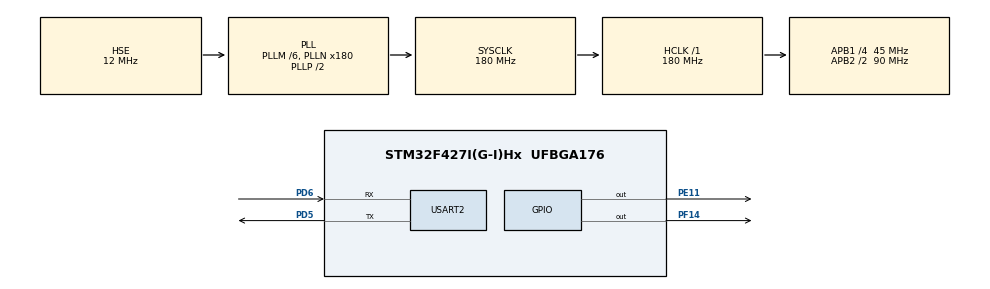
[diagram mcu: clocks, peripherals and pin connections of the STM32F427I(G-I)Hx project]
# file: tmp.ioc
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Dma.Request0=USART2_TX
Dma.USART2_TX.0.Direction=DMA_MEMORY_TO_PERIPH
Dma.USART2_TX.0.FIFOMode=DMA_FIFOMODE_DISABLE
Dma.USART2_TX.0.Instance=DMA1_Stream6
Dma.USART2_TX.0.MemDataAlignment=DMA_MDATAALIGN_BYTE
Dma.USART2_TX.0.MemInc=DMA_MINC_ENABLE
Dma.USART2_TX.0.Mode=DMA_NORMAL
Dma.USART2_TX.0.PeriphDataAlignment=DMA_PDATAALIGN_BYTE
Dma.USART2_TX.0.PeriphInc=DMA_PINC_DISABLE
Dma.USART2_TX.0.Priority=DMA_PRIORITY_LOW
Mcu.Family=STM32F4
Mcu.Name=STM32F427I(G-I)Hx
Mcu.Package=UFBGA176
NVIC.DMA1_Stream6_IRQn=true\:0\:0\:false\:false\:true\:false
NVIC.PriorityGroup=NVIC_PRIORITYGROUP_4
NVIC.RCC_IRQn=true\:0\:0\:false\:false\:true\:true
NVIC.USART2_IRQn=true\:0\:0\:false\:false\:true\:true
PD5.Mode=Asynchronous
PD5.Signal=USART2_TX
PD6.Mode=Asynchronous
PD6.Signal=USART2_RX
PE11.PinState=GPIO_PIN_SET
PE11.Signal=GPIO_Output
PF14.PinState=GPIO_PIN_SET
PF14.Signal=GPIO_Output
PH0/OSC_IN.Mode=HSE-External-Oscillator
PH0/OSC_IN.Signal=RCC_OSC_IN
PH1/OSC_OUT.Mode=HSE-External-Oscillator
PH1/OSC_OUT.Signal=RCC_OSC_OUT
ProjectManager.HeapSize=0x200
ProjectManager.StackSize=0x400
ProjectManager.TargetToolchain=MDK-ARM V5
RCC.48MHZClocksFreq_Value=90000000
RCC.AHBFreq_Value=180000000
RCC.APB1CLKDivider=RCC_HCLK_DIV4
RCC.APB1Freq_Value=45000000
RCC.APB1TimFreq_Value=90000000
RCC.APB2CLKDivider=RCC_HCLK_DIV2
RCC.APB2Freq_Value=90000000
RCC.APB2TimFreq_Value=180000000
RCC.CortexFreq_Value=180000000
RCC.HCLKFreq_Value=180000000
RCC.HSE_VALUE=12000000
RCC.HSI_VALUE=16000000
RCC.LSE_VALUE=32768
RCC.PLLM=6
RCC.PLLN=180
RCC.PLLSourceVirtual=RCC_PLLSOURCE_HSE
RCC.SYSCLKFreq_VALUE=180000000
RCC.SYSCLKSource=RCC_SYSCLKSOURCE_PLLCLK
RCC.VCOOutputFreq_Value=360000000
USART2.VirtualMode=VM_ASYNC
board=custom

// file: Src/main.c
/* USER CODE BEGIN Header */
/**
  ******************************************************************************
  * @file           : main.c
  * @brief          : Main program body
  ******************************************************************************
  ** This notice applies to any and all portions of this file
  * that are not between comment pairs USER CODE BEGIN and
  * USER CODE END. Other portions of this file, whether
  * inserted by the user or by software development tools
  * are owned by their respective copyright owners.
  *
  * COPYRIGHT(c) 2019 STMicroelectronics
  *
  * Redistribution and use in source and binary forms, with or without modification,
  * are permitted provided that the following conditions are met:
  *   1. Redistributions of source code must retain the above copyright notice,
  *      this list of conditions and the following disclaimer.
  *   2. Redistributions in binary form must reproduce the above copyright notice,
  *      this list of conditions and the following disclaimer in the documentation
  *      and/or other materials provided with the distribution.
  *   3. Neither the name of STMicroelectronics nor the names of its contributors
  *      may be used to endorse or promote products derived from this software
  *      without specific prior written permission.
  *
  * THIS SOFTWARE IS PROVIDED BY THE COPYRIGHT HOLDERS AND CONTRIBUTORS "AS IS"
  * AND ANY EXPRESS OR IMPLIED WARRANTIES, INCLUDING, BUT NOT LIMITED TO, THE
  * IMPLIED WARRANTIES OF MERCHANTABILITY AND FITNESS FOR A PARTICULAR PURPOSE ARE
  * DISCLAIMED. IN NO EVENT SHALL THE COPYRIGHT HOLDER OR CONTRIBUTORS BE LIABLE
  * FOR ANY DIRECT, INDIRECT, INCIDENTAL, SPECIAL, EXEMPLARY, OR CONSEQUENTIAL
  * DAMAGES (INCLUDING, BUT NOT LIMITED TO, PROCUREMENT OF SUBSTITUTE GOODS OR
  * SERVICES; LOSS OF USE, DATA, OR PROFITS; OR BUSINESS INTERRUPTION) HOWEVER
  * CAUSED AND ON ANY THEORY OF LIABILITY, WHETHER IN CONTRACT, STRICT LIABILITY,
  * OR TORT (INCLUDING NEGLIGENCE OR OTHERWISE) ARISING IN ANY WAY OUT OF THE USE
  * OF THIS SOFTWARE, EVEN IF ADVISED OF THE POSSIBILITY OF SUCH DAMAGE.
  *
  ******************************************************************************
  */
/* USER CODE END Header */

#include "main.h"
#include "dma.h"
#include "usart.h"
#include "gpio.h"

/* USER CODE BEGIN Includes */
#include "judge.h"
#include "string.h"
/* USER CODE END Includes */

void SystemClock_Config(void);

/* USER CODE BEGIN 0 */

// RX的中断回调函数
void HAL_UART_RxCpltCallback(UART_HandleTypeDef *huart)
{
	unpack(RX_BUF, &tmp_frame);
	// getPowerHeat(tmp_frame, &JData.PowerHeat);
	getJData(tmp_frame, &JData);
  HAL_GPIO_TogglePin(GPIOF, GPIO_PIN_14);
	memset((void *)RX_BUF, 0, RX_BUF_LEN * sizeof(uint8_t));
  HAL_UART_Receive_IT(&huart2, (uint8_t *)RX_BUF, RX_BUF_LEN);
}
/* USER CODE END 0 */

int main(void)
{

  /* MCU Configuration--------------------------------------------------------*/

  /* Reset of all peripherals, Initializes the Flash interface and the Systick. */
  HAL_Init();

  /* Configure the system clock */
  SystemClock_Config();

  /* Initialize all configured peripherals */
  MX_GPIO_Init();
  MX_DMA_Init();
  MX_USART2_UART_Init();
  /* USER CODE BEGIN 2 */
  HAL_UART_Receive_IT(&huart2, (uint8_t *)RX_BUF, RX_BUF_LEN);
  /* USER CODE END 2 */

  /* Infinite loop */
  while (1)
  {

    /* USER CODE BEGIN 3 */
    // HAL_UART_Transmit_DMA(&huart2, s, 3);
  }
  /* USER CODE END 3 */
}

void SystemClock_Config(void)
{
  RCC_OscInitTypeDef RCC_OscInitStruct = {0};
  RCC_ClkInitTypeDef RCC_ClkInitStruct = {0};

  /**Configure the main internal regulator output voltage
  */
  __HAL_RCC_PWR_CLK_ENABLE();
  __HAL_PWR_VOLTAGESCALING_CONFIG(PWR_REGULATOR_VOLTAGE_SCALE1);
  /**Initializes the CPU, AHB and APB busses clocks
  */
  RCC_OscInitStruct.OscillatorType = RCC_OSCILLATORTYPE_HSE;
  RCC_OscInitStruct.HSEState = RCC_HSE_ON;
  RCC_OscInitStruct.PLL.PLLState = RCC_PLL_ON;
  RCC_OscInitStruct.PLL.PLLSource = RCC_PLLSOURCE_HSE;
  RCC_OscInitStruct.PLL.PLLM = 6;
  RCC_OscInitStruct.PLL.PLLN = 180;
  RCC_OscInitStruct.PLL.PLLP = RCC_PLLP_DIV2;
  RCC_OscInitStruct.PLL.PLLQ = 4;
  if (HAL_RCC_OscConfig(&RCC_OscInitStruct) != HAL_OK)
  {
    Error_Handler();
  }
  /**Activate the Over-Drive mode
  */
  if (HAL_PWREx_EnableOverDrive() != HAL_OK)
  {
    Error_Handler();
  }
  /**Initializes the CPU, AHB and APB busses clocks
  */
  RCC_ClkInitStruct.ClockType = RCC_CLOCKTYPE_HCLK|RCC_CLOCKTYPE_SYSCLK
                              |RCC_CLOCKTYPE_PCLK1|RCC_CLOCKTYPE_PCLK2;
  RCC_ClkInitStruct.SYSCLKSource = RCC_SYSCLKSOURCE_PLLCLK;
  RCC_ClkInitStruct.AHBCLKDivider = RCC_SYSCLK_DIV1;
  RCC_ClkInitStruct.APB1CLKDivider = RCC_HCLK_DIV4;
  RCC_ClkInitStruct.APB2CLKDivider = RCC_HCLK_DIV2;

  if (HAL_RCC_ClockConfig(&RCC_ClkInitStruct, FLASH_LATENCY_5) != HAL_OK)
  {
    Error_Handler();
  }
}

void Error_Handler(void)
{
}

/************************ (C) COPYRIGHT STMicroelectronics *****END OF FILE****/
